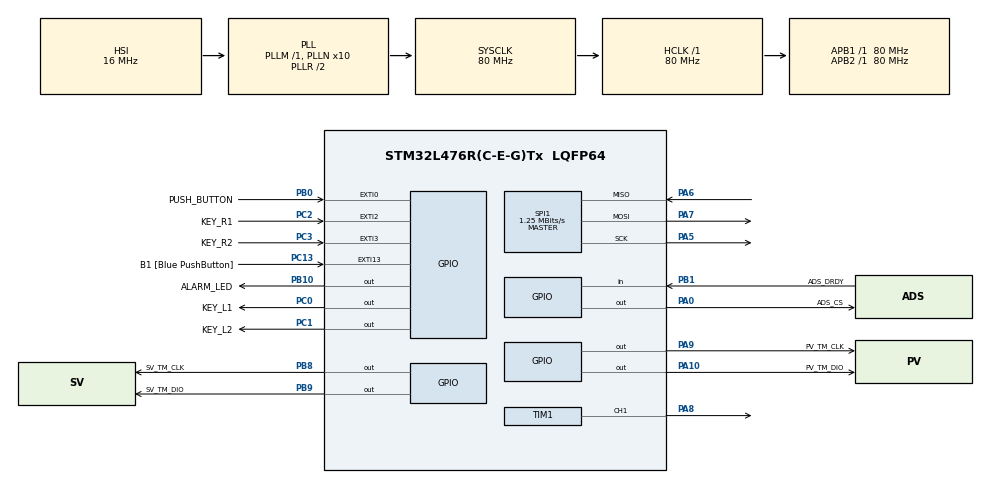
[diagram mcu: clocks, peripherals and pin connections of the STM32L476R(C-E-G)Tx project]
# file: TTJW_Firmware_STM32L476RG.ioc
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Mcu.Family=STM32L4
Mcu.Name=STM32L476R(C-E-G)Tx
Mcu.Package=LQFP64
NVIC.EXTI0_IRQn=true\:0\:0\:false\:false\:true\:true\:true\:true
NVIC.EXTI15_10_IRQn=true\:0\:0\:false\:false\:true\:true\:true\:true
NVIC.EXTI2_IRQn=true\:0\:0\:false\:false\:true\:true\:true\:true
NVIC.EXTI3_IRQn=true\:0\:0\:false\:false\:true\:true\:true\:true
NVIC.PriorityGroup=NVIC_PRIORITYGROUP_4
PA0.GPIO_Label=ADS_CS
PA0.GPIO_Speed=GPIO_SPEED_FREQ_LOW
PA0.PinState=GPIO_PIN_SET
PA0.Signal=GPIO_Output
PA10.GPIO_Label=PV_TM_DIO
PA10.PinState=GPIO_PIN_SET
PA10.Signal=GPIO_Output
PA13\ (JTMS-SWDIO).GPIO_Label=TMS
PA13\ (JTMS-SWDIO).Mode=Serial_Wire
PA13\ (JTMS-SWDIO).Signal=SYS_JTMS-SWDIO
PA14\ (JTCK-SWCLK).GPIO_Label=TCK
PA14\ (JTCK-SWCLK).Mode=Serial_Wire
PA14\ (JTCK-SWCLK).Signal=SYS_JTCK-SWCLK
PA5.Mode=Full_Duplex_Master
PA5.Signal=SPI1_SCK
PA6.Mode=Full_Duplex_Master
PA6.Signal=SPI1_MISO
PA7.Mode=Full_Duplex_Master
PA7.Signal=SPI1_MOSI
PA8.Signal=S_TIM1_CH1
PA9.GPIO_Label=PV_TM_CLK
PA9.PinState=GPIO_PIN_SET
PA9.Signal=GPIO_Output
PB0.GPIO_Label=PUSH_BUTTON
PB0.GPIO_ModeDefaultEXTI=GPIO_MODE_IT_FALLING
PB0.GPIO_PuPd=GPIO_PULLUP
PB0.Signal=GPXTI0
PB1.GPIO_Label=ADS_DRDY
PB1.Signal=GPIO_Input
PB10.GPIO_Label=ALARM_LED
PB10.Signal=GPIO_Output
PB3\ (JTDO-TRACESWO).GPIO_Label=SWO
PB3\ (JTDO-TRACESWO).Signal=SYS_JTDO-SWO
PB8.GPIO_Label=SV_TM_CLK
PB8.PinState=GPIO_PIN_SET
PB8.Signal=GPIO_Output
PB9.GPIO_Label=SV_TM_DIO
PB9.PinState=GPIO_PIN_SET
PB9.Signal=GPIO_Output
PC0.GPIO_Label=KEY_L1
PC0.GPIO_PuPd=GPIO_NOPULL
PC0.PinState=GPIO_PIN_SET
PC0.Signal=GPIO_Output
PC1.GPIO_Label=KEY_L2
PC1.PinState=GPIO_PIN_SET
PC1.Signal=GPIO_Output
PC13.GPIO_Label=B1 [Blue PushButton]
PC13.GPIO_ModeDefaultEXTI=GPIO_MODE_IT_RISING_FALLING
PC13.GPIO_PuPd=GPIO_NOPULL
PC13.Signal=GPXTI13
PC14-OSC32_IN\ (PC14).Mode=LSE-External-Oscillator
PC14-OSC32_IN\ (PC14).Signal=RCC_OSC32_IN
PC15-OSC32_OUT\ (PC15).Mode=LSE-External-Oscillator
PC15-OSC32_OUT\ (PC15).Signal=RCC_OSC32_OUT
PC2.GPIO_Label=KEY_R1
PC2.GPIO_ModeDefaultEXTI=GPIO_MODE_IT_FALLING
PC2.GPIO_PuPd=GPIO_PULLUP
PC2.Signal=GPXTI2
PC3.GPIO_Label=KEY_R2
PC3.GPIO_ModeDefaultEXTI=GPIO_MODE_IT_FALLING
PC3.GPIO_PuPd=GPIO_PULLUP
PC3.Signal=GPXTI3
PH0-OSC_IN\ (PH0).Signal=RCC_OSC_IN
PH1-OSC_OUT\ (PH1).Signal=RCC_OSC_OUT
ProjectManager.HeapSize=0x200
ProjectManager.StackSize=0x400
ProjectManager.TargetToolchain=STM32CubeIDE
RCC.ADCFreq_Value=64000000
RCC.AHBFreq_Value=80000000
RCC.APB1Freq_Value=80000000
RCC.APB1TimFreq_Value=80000000
RCC.APB2Freq_Value=80000000
RCC.APB2TimFreq_Value=80000000
RCC.CortexFreq_Value=80000000
RCC.HCLKFreq_Value=80000000
RCC.HSE_VALUE=8000000
RCC.HSI_VALUE=16000000
RCC.MSI_VALUE=4000000
RCC.PLLN=10
RCC.PLLSourceVirtual=RCC_PLLSOURCE_HSI
RCC.PREFETCH_ENABLE=1
RCC.SYSCLKFreq_VALUE=80000000
RCC.SYSCLKSource=RCC_SYSCLKSOURCE_PLLCLK
RCC.USBFreq_Value=64000000
RCC.VCOOutputFreq_Value=160000000
SH.S_TIM1_CH1.0=TIM1_CH1,PWM Generation1 CH1
SPI1.BaudRatePrescaler=SPI_BAUDRATEPRESCALER_64
SPI1.CLKPhase=SPI_PHASE_2EDGE
SPI1.CalculateBaudRate=1.25 MBits/s
SPI1.DataSize=SPI_DATASIZE_8BIT
SPI1.Direction=SPI_DIRECTION_2LINES
SPI1.Mode=SPI_MODE_MASTER
SPI1.VirtualType=VM_MASTER
TIM1.Channel-PWM\ Generation1\ CH1=TIM_CHANNEL_1
TIM1.Period=19999
TIM1.Prescaler=7999
VP_TIM1_VS_ClockSourceINT.Mode=Internal
board=NUCLEO-L476RG

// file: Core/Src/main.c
/* USER CODE BEGIN Header */
/**
  ******************************************************************************
  * @file           : main.c
  * @brief          : TTJW application entry point and STM32 board initialization
  *
  * Application modules are separated into dedicated .c/.h pairs:
  *   - ADS1220 driver
  *   - PT100 conversion
  *   - Heater/PID control
  *   - Matrix keypad
  *   - Dual TM1637 seven-segment displays
  *   - Shared application state and configuration
  ******************************************************************************
  */
/* USER CODE END Header */
#include "main.h"

/* USER CODE BEGIN Includes */
#include "ads1220.h"
#include "pt100.h"
#include "keypad.h"
#include "ttjw_display.h"
#include "ttjw_state.h"
#include "heater_control.h"
#include "ttjw_config.h"
#include <limits.h>
#include <math.h>
/* USER CODE END Includes */

SPI_HandleTypeDef hspi1;

TIM_HandleTypeDef htim1;

void SystemClock_Config(void);
static void MX_GPIO_Init(void);
static void MX_SPI1_Init(void);
static void MX_TIM1_Init(void);

static uint8_t TTJW_AlarmEvaluate(float correctedPvC)
{
  float upper = g_setValue + g_alarmValue;
  float lower = g_setValue - g_alarmValue;
  uint8_t high = (correctedPvC >= upper) ? 1U : 0U;
  uint8_t low = (correctedPvC <= lower) ? 1U : 0U;

  switch (g_alarmType)
  {
    case 1U: return high;                    /* UP */
    case 2U: return low;                     /* LO */
    case 3U: return (high || low) ? 1U : 0U; /* P-L */
    case 0U:
    default: return 0U;                      /* OFF */
  }
}

int main(void)
{
  int32_t raw;
  float resistance;
  float measuredC;
  float correctedC;
  uint8_t validSample;

  HAL_Init();
  SystemClock_Config();
  MX_GPIO_Init();
  MX_SPI1_Init();
  MX_TIM1_Init();

  /* Integrated TTJW test: enable the complete keypad/menu interface. */
  Keypad_Init();
  TTJW_DisplayInit();

  /* Start with a known-safe output state. */
  HAL_GPIO_WritePin(ALARM_LED_GPIO_Port, ALARM_LED_Pin, GPIO_PIN_RESET);
  g_heaterDutyPercent = 0U;
  Heater_Init();
  Heater_SetDuty(0U);
  PID_Reset();

  HAL_GPIO_WritePin(ADS_CS_GPIO_Port, ADS_CS_Pin, GPIO_PIN_SET);
  ADS1220_Reset();
  ADS1220_WriteRegisters();
  ADS1220_StartConversion();

  g_setValue = 37.0f; /* Fixed test setpoint: 37.0 C. */
  g_errorAdjustment = 0.0f;
  g_temperatureUnit = TEMP_UNIT_CELSIUS;
  g_uiState = UI_HOME;
  g_latestTemperature = 0.0f;
  g_measuredTemperature = 0.0f;
  g_sensorValid = 0U;
  g_errorDisplayActive = 1U;
  TTJW_DisplayUpdate();

  while (1)
  {
    /* Run the complete S1-S4 keypad/menu state machine. */
    Keypad_Process();

    raw = ADS1220_ReadConversion();
    validSample = 0U;

    if (raw != INT32_MIN)
    {
      resistance = CalculateResistance(raw);
      if (isfinite(resistance) &&
          (resistance >= TTJW_PT100_RESISTANCE_MIN_OHMS) &&
          (resistance <= TTJW_PT100_RESISTANCE_MAX_OHMS))
      {
        measuredC = ResistanceToTemperature(resistance);
        if (isfinite(measuredC))
        {
          /* SFT is maintained internally in Celsius; corrected PV is the
           * single feedback value used by display, alarm and PID. */
          correctedC = measuredC + g_errorAdjustment;
          g_measuredTemperature = measuredC;
          g_latestTemperature = correctedC;
          g_sensorValid = 1U;
          g_errorDisplayActive = 0U;
          validSample = 1U;
        }
      }
    }

    if (validSample != 0U)
    {
      g_alarmActive = TTJW_AlarmEvaluate(g_latestTemperature);
      HAL_GPIO_WritePin(ALARM_LED_GPIO_Port, ALARM_LED_Pin,
          (g_alarmActive != 0U) ? GPIO_PIN_SET : GPIO_PIN_RESET);

#if TTJW_PID_PWM_TEST_MODE
      /* Bench-test mode: drive PA8 with PID demand. Keep heater power disconnected. */
      Heater_SetDuty(Heater_CalculateDuty(g_latestTemperature));
#else
      /* Production-safe default: power-stage output remains inhibited. */
      Heater_SetDuty(0U);
#endif
    }
    else
    {
      /* ADC timeout or implausible RTD resistance: fail safe. */
      g_sensorValid = 0U;
      g_errorDisplayActive = 1U;
      g_alarmActive = 0U;
      HAL_GPIO_WritePin(ALARM_LED_GPIO_Port, ALARM_LED_Pin, GPIO_PIN_RESET);
      Heater_SetDuty(0U);
      PID_Reset();
    }

    TTJW_DisplayUpdate();
    ADS1220_StartConversion();
    HAL_Delay(2U);
  }
}

void SystemClock_Config(void)
{
  RCC_OscInitTypeDef RCC_OscInitStruct = {0};
  RCC_ClkInitTypeDef RCC_ClkInitStruct = {0};

  /** Configure the main internal regulator output voltage
  */
  if (HAL_PWREx_ControlVoltageScaling(PWR_REGULATOR_VOLTAGE_SCALE1) != HAL_OK)
  {
    Error_Handler();
  }

  /** Initializes the RCC Oscillators according to the specified parameters
  * in the RCC_OscInitTypeDef structure.
  */
  RCC_OscInitStruct.OscillatorType = RCC_OSCILLATORTYPE_HSI;
  RCC_OscInitStruct.HSIState = RCC_HSI_ON;
  RCC_OscInitStruct.HSICalibrationValue = RCC_HSICALIBRATION_DEFAULT;
  RCC_OscInitStruct.PLL.PLLState = RCC_PLL_ON;
  RCC_OscInitStruct.PLL.PLLSource = RCC_PLLSOURCE_HSI;
  RCC_OscInitStruct.PLL.PLLM = 1;
  RCC_OscInitStruct.PLL.PLLN = 10;
  RCC_OscInitStruct.PLL.PLLP = RCC_PLLP_DIV7;
  RCC_OscInitStruct.PLL.PLLQ = RCC_PLLQ_DIV2;
  RCC_OscInitStruct.PLL.PLLR = RCC_PLLR_DIV2;
  if (HAL_RCC_OscConfig(&RCC_OscInitStruct) != HAL_OK)
  {
    Error_Handler();
  }

  /** Initializes the CPU, AHB and APB buses clocks
  */
  RCC_ClkInitStruct.ClockType = RCC_CLOCKTYPE_HCLK|RCC_CLOCKTYPE_SYSCLK
                              |RCC_CLOCKTYPE_PCLK1|RCC_CLOCKTYPE_PCLK2;
  RCC_ClkInitStruct.SYSCLKSource = RCC_SYSCLKSOURCE_PLLCLK;
  RCC_ClkInitStruct.AHBCLKDivider = RCC_SYSCLK_DIV1;
  RCC_ClkInitStruct.APB1CLKDivider = RCC_HCLK_DIV1;
  RCC_ClkInitStruct.APB2CLKDivider = RCC_HCLK_DIV1;

  if (HAL_RCC_ClockConfig(&RCC_ClkInitStruct, FLASH_LATENCY_4) != HAL_OK)
  {
    Error_Handler();
  }
}

static void MX_SPI1_Init(void)
{

  /* SPI1 parameter configuration*/
  hspi1.Instance = SPI1;
  hspi1.Init.Mode = SPI_MODE_MASTER;
  hspi1.Init.Direction = SPI_DIRECTION_2LINES;
  hspi1.Init.DataSize = SPI_DATASIZE_8BIT;
  hspi1.Init.CLKPolarity = SPI_POLARITY_LOW;
  hspi1.Init.CLKPhase = SPI_PHASE_2EDGE;
  hspi1.Init.NSS = SPI_NSS_SOFT;
  hspi1.Init.BaudRatePrescaler = SPI_BAUDRATEPRESCALER_64;
  hspi1.Init.FirstBit = SPI_FIRSTBIT_MSB;
  hspi1.Init.TIMode = SPI_TIMODE_DISABLE;
  hspi1.Init.CRCCalculation = SPI_CRCCALCULATION_DISABLE;
  hspi1.Init.CRCPolynomial = 7;
  hspi1.Init.CRCLength = SPI_CRC_LENGTH_DATASIZE;
  hspi1.Init.NSSPMode = SPI_NSS_PULSE_DISABLE;
  if (HAL_SPI_Init(&hspi1) != HAL_OK)
  {
    Error_Handler();
  }

}

static void MX_TIM1_Init(void)
{

  TIM_ClockConfigTypeDef sClockSourceConfig = {0};
  TIM_MasterConfigTypeDef sMasterConfig = {0};
  TIM_OC_InitTypeDef sConfigOC = {0};
  TIM_BreakDeadTimeConfigTypeDef sBreakDeadTimeConfig = {0};

  htim1.Instance = TIM1;
  htim1.Init.Prescaler = 7999;
  htim1.Init.CounterMode = TIM_COUNTERMODE_UP;
  htim1.Init.Period = 19999;
  htim1.Init.ClockDivision = TIM_CLOCKDIVISION_DIV1;
  htim1.Init.RepetitionCounter = 0;
  htim1.Init.AutoReloadPreload = TIM_AUTORELOAD_PRELOAD_DISABLE;
  if (HAL_TIM_Base_Init(&htim1) != HAL_OK)
  {
    Error_Handler();
  }
  sClockSourceConfig.ClockSource = TIM_CLOCKSOURCE_INTERNAL;
  if (HAL_TIM_ConfigClockSource(&htim1, &sClockSourceConfig) != HAL_OK)
  {
    Error_Handler();
  }
  if (HAL_TIM_PWM_Init(&htim1) != HAL_OK)
  {
    Error_Handler();
  }
  sMasterConfig.MasterOutputTrigger = TIM_TRGO_RESET;
  sMasterConfig.MasterOutputTrigger2 = TIM_TRGO2_RESET;
  sMasterConfig.MasterSlaveMode = TIM_MASTERSLAVEMODE_DISABLE;
  if (HAL_TIMEx_MasterConfigSynchronization(&htim1, &sMasterConfig) != HAL_OK)
  {
    Error_Handler();
  }
  sConfigOC.OCMode = TIM_OCMODE_PWM1;
  sConfigOC.Pulse = 0;
  sConfigOC.OCPolarity = TIM_OCPOLARITY_HIGH;
  sConfigOC.OCNPolarity = TIM_OCNPOLARITY_HIGH;
  sConfigOC.OCFastMode = TIM_OCFAST_DISABLE;
  sConfigOC.OCIdleState = TIM_OCIDLESTATE_RESET;
  sConfigOC.OCNIdleState = TIM_OCNIDLESTATE_RESET;
  if (HAL_TIM_PWM_ConfigChannel(&htim1, &sConfigOC, TIM_CHANNEL_1) != HAL_OK)
  {
    Error_Handler();
  }
  sBreakDeadTimeConfig.OffStateRunMode = TIM_OSSR_DISABLE;
  sBreakDeadTimeConfig.OffStateIDLEMode = TIM_OSSI_DISABLE;
  sBreakDeadTimeConfig.LockLevel = TIM_LOCKLEVEL_OFF;
  sBreakDeadTimeConfig.DeadTime = 0;
  sBreakDeadTimeConfig.BreakState = TIM_BREAK_DISABLE;
  sBreakDeadTimeConfig.BreakPolarity = TIM_BREAKPOLARITY_HIGH;
  sBreakDeadTimeConfig.BreakFilter = 0;
  sBreakDeadTimeConfig.Break2State = TIM_BREAK2_DISABLE;
  sBreakDeadTimeConfig.Break2Polarity = TIM_BREAK2POLARITY_HIGH;
  sBreakDeadTimeConfig.Break2Filter = 0;
  sBreakDeadTimeConfig.AutomaticOutput = TIM_AUTOMATICOUTPUT_DISABLE;
  if (HAL_TIMEx_ConfigBreakDeadTime(&htim1, &sBreakDeadTimeConfig) != HAL_OK)
  {
    Error_Handler();
  }
  HAL_TIM_MspPostInit(&htim1);

}

static void MX_GPIO_Init(void)
{
  GPIO_InitTypeDef GPIO_InitStruct = {0};

  /* GPIO Ports Clock Enable */
  __HAL_RCC_GPIOC_CLK_ENABLE();
  __HAL_RCC_GPIOH_CLK_ENABLE();
  __HAL_RCC_GPIOA_CLK_ENABLE();
  __HAL_RCC_GPIOB_CLK_ENABLE();

  /*Configure GPIO pin Output Level */
  HAL_GPIO_WritePin(GPIOC, KEY_L1_Pin|KEY_L2_Pin, GPIO_PIN_SET);

  /*Configure GPIO pin Output Level */
  HAL_GPIO_WritePin(GPIOA, ADS_CS_Pin|PV_TM_CLK_Pin|PV_TM_DIO_Pin, GPIO_PIN_SET);

  /*Configure GPIO pin Output Level */
  HAL_GPIO_WritePin(ALARM_LED_GPIO_Port, ALARM_LED_Pin, GPIO_PIN_RESET);

  /*Configure GPIO pin Output Level */
  HAL_GPIO_WritePin(GPIOB, SV_TM_CLK_Pin|SV_TM_DIO_Pin, GPIO_PIN_SET);

  /*Configure GPIO pin : B1_Pin */
  GPIO_InitStruct.Pin = B1_Pin;
  GPIO_InitStruct.Mode = GPIO_MODE_IT_RISING_FALLING;
  GPIO_InitStruct.Pull = GPIO_NOPULL;
  HAL_GPIO_Init(B1_GPIO_Port, &GPIO_InitStruct);

  /*Configure GPIO pins : KEY_L1_Pin KEY_L2_Pin */
  GPIO_InitStruct.Pin = KEY_L1_Pin|KEY_L2_Pin;
  GPIO_InitStruct.Mode = GPIO_MODE_OUTPUT_PP;
  GPIO_InitStruct.Pull = GPIO_NOPULL;
  GPIO_InitStruct.Speed = GPIO_SPEED_FREQ_LOW;
  HAL_GPIO_Init(GPIOC, &GPIO_InitStruct);

  /*Configure GPIO pins : KEY_R1_Pin KEY_R2_Pin */
  GPIO_InitStruct.Pin = KEY_R1_Pin|KEY_R2_Pin;
  GPIO_InitStruct.Mode = GPIO_MODE_IT_FALLING;
  GPIO_InitStruct.Pull = GPIO_PULLUP;
  HAL_GPIO_Init(GPIOC, &GPIO_InitStruct);

  /*Configure GPIO pins : ADS_CS_Pin PV_TM_CLK_Pin PV_TM_DIO_Pin */
  GPIO_InitStruct.Pin = ADS_CS_Pin|PV_TM_CLK_Pin|PV_TM_DIO_Pin;
  GPIO_InitStruct.Mode = GPIO_MODE_OUTPUT_PP;
  GPIO_InitStruct.Pull = GPIO_NOPULL;
  GPIO_InitStruct.Speed = GPIO_SPEED_FREQ_LOW;
  HAL_GPIO_Init(GPIOA, &GPIO_InitStruct);

  /*Configure GPIO pin : PUSH_BUTTON_Pin */
  GPIO_InitStruct.Pin = PUSH_BUTTON_Pin;
  GPIO_InitStruct.Mode = GPIO_MODE_IT_FALLING;
  GPIO_InitStruct.Pull = GPIO_PULLUP;
  HAL_GPIO_Init(PUSH_BUTTON_GPIO_Port, &GPIO_InitStruct);

  /*Configure GPIO pin : ADS_DRDY_Pin */
  GPIO_InitStruct.Pin = ADS_DRDY_Pin;
  GPIO_InitStruct.Mode = GPIO_MODE_INPUT;
  GPIO_InitStruct.Pull = GPIO_NOPULL;
  HAL_GPIO_Init(ADS_DRDY_GPIO_Port, &GPIO_InitStruct);

  /*Configure GPIO pins : ALARM_LED_Pin SV_TM_CLK_Pin SV_TM_DIO_Pin */
  GPIO_InitStruct.Pin = ALARM_LED_Pin|SV_TM_CLK_Pin|SV_TM_DIO_Pin;
  GPIO_InitStruct.Mode = GPIO_MODE_OUTPUT_PP;
  GPIO_InitStruct.Pull = GPIO_NOPULL;
  GPIO_InitStruct.Speed = GPIO_SPEED_FREQ_LOW;
  HAL_GPIO_Init(GPIOB, &GPIO_InitStruct);

  /* EXTI interrupt init*/
  HAL_NVIC_SetPriority(EXTI0_IRQn, 0, 0);
  HAL_NVIC_EnableIRQ(EXTI0_IRQn);

  HAL_NVIC_SetPriority(EXTI2_IRQn, 0, 0);
  HAL_NVIC_EnableIRQ(EXTI2_IRQn);

  HAL_NVIC_SetPriority(EXTI3_IRQn, 0, 0);
  HAL_NVIC_EnableIRQ(EXTI3_IRQn);

  HAL_NVIC_SetPriority(EXTI15_10_IRQn, 0, 0);
  HAL_NVIC_EnableIRQ(EXTI15_10_IRQn);

}

void Error_Handler(void)
{
  __disable_irq();
  while (1)
  {
  }
}
